BO_ 96 CAR_OVERALL_SIGNALS2: 64 XXX
 SG_ CRC1 : 7|8@0+ (1,0) [0|255] "" XXX
 SG_ COUNTER1 : 59|4@0+ (1,0) [0|15] "" XXX
 SG_ CRC2 : 71|8@0+ (1,0) [0|255] "" XXX
 SG_ GAS_POSITION : 79|8@0+ (0.393700787,0) [0|255] "%" XXX
 SG_ BRAKE_SIGNAL : 86|1@0+ (1,0) [0|1] "" XXX
 SG_ ACC_GAS_POSITION : 103|8@0+ (0.393700787,0) [0|255] "%" XXX
 SG_ COUNTER2 : 123|4@0+ (1,0) [0|15] "" XXX
 SG_ CRC3 : 135|8@0+ (1,0) [0|255] "" XXX
 SG_ REQ_REVIEW_UND_SIGNAL : 143|10@0+ (1,0) [0|255] "" XXX
 SG_ REQ_REVIEW_POWER_CONSUMPTION : 144|9@0+ (1,-175) [0|511] "" XXX
 SG_ REQ_REVIEW_POWER_CONSUMPTION2 : 180|9@0+ (1,-176) [0|511] "" XXX
 SG_ COUNTER3 : 187|4@0+ (1,0) [0|15] "" XXX
 SG_ REQ_REVIEW_POWER_STATE_SIGNAL : 302|4@0+ (1,0) [0|15] "" XXX
 SG_ REQ_REVIEW_POWER_STATE_SIGNAL2 : 370|1@0+ (1,0) [0|1] "" XXX

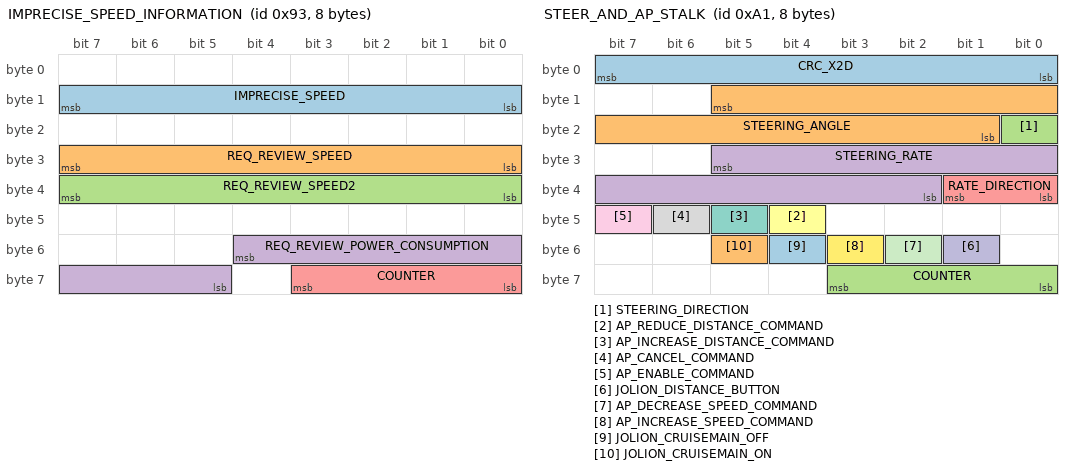
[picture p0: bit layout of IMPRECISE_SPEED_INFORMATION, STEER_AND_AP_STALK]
BO_ 147 IMPRECISE_SPEED_INFORMATION: 8 XXX
 SG_ IMPRECISE_SPEED : 15|8@0+ (3.5,0) [0|255] "kph" XXX
 SG_ REQ_REVIEW_SPEED : 31|8@0+ (0.430107526,0) [0|255] "Kph" XXX
 SG_ REQ_REVIEW_SPEED2 : 39|8@0+ (0.430107526,0) [0|255] "Kph" XXX
 SG_ REQ_REVIEW_POWER_CONSUMPTION : 52|8@0+ (1,0) [0|255] "" XXX
 SG_ COUNTER : 59|4@0+ (1,0) [0|15] "" XXX

BO_ 161 STEER_AND_AP_STALK: 8 XXX
 SG_ CRC_X2D : 7|8@0+ (1,0) [0|255] "" XXX
 SG_ STEERING_ANGLE : 13|13@0+ (0.1,0) [0|65535] "degs" XXX
 SG_ STEERING_DIRECTION : 16|1@0+ (1,0) [0|1] "" XXX
 SG_ STEERING_RATE : 29|12@0+ (0.004,0) [0|4095] "" XXX
 SG_ RATE_DIRECTION : 33|2@0+ (1,0) [0|3] "" XXX
 SG_ AP_REDUCE_DISTANCE_COMMAND : 44|1@0+ (1,0) [0|1] "" XXX
 SG_ AP_INCREASE_DISTANCE_COMMAND : 45|1@0+ (1,0) [0|1] "AUTOPILOT_STALK" XXX
 SG_ AP_CANCEL_COMMAND : 46|1@0+ (1,0) [0|1] "" XXX
 SG_ AP_ENABLE_COMMAND : 47|1@0+ (1,0) [0|1] "" XXX
 SG_ JOLION_DISTANCE_BUTTON : 49|1@0+ (1,0) [0|1] "" XXX
 SG_ AP_DECREASE_SPEED_COMMAND : 50|1@0+ (1,0) [0|1] "" XXX
 SG_ AP_INCREASE_SPEED_COMMAND : 51|1@0+ (1,0) [0|1] "" XXX
 SG_ JOLION_CRUISEMAIN_OFF : 52|1@0+ (1,0) [0|1] "" XXX
 SG_ JOLION_CRUISEMAIN_ON : 53|1@0+ (1,0) [0|1] "" XXX
 SG_ COUNTER : 59|4@0+ (1,0) [0|255] "" XXX

BO_ 259 SPEED: 64 XXX
 SG_ CRC : 199|8@0+ (1,0) [0|255] "" XXX
 SG_ UNDEFINED_ACCUMULATOR : 207|8@0+ (1,0) [0|255] "" XXX
 SG_ UNDEFINED_COUNTER : 215|8@0+ (1,0) [0|255] "" XXX
 SG_ ODD_GAS_POSITION : 231|8@0+ (1,0) [0|255] "" XXX
 SG_ SPEED : 239|8@0+ (1,0) [0|255] "Khp" XXX
 SG_ COUNTER2 : 251|4@0+ (1,0) [0|15] "" XXX

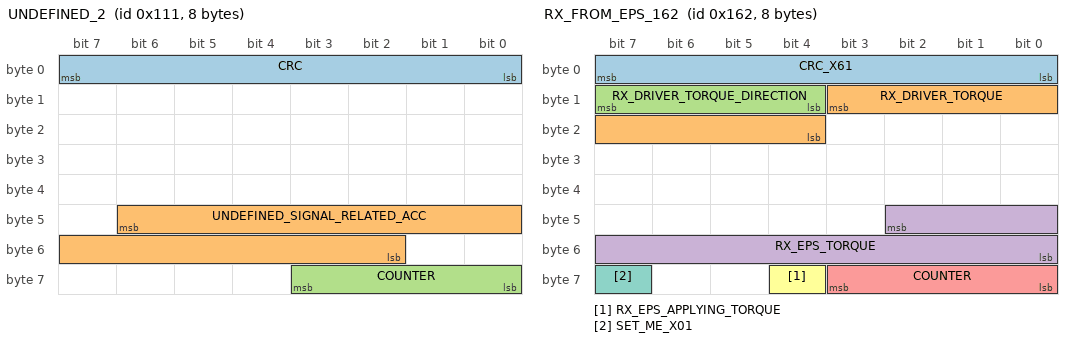
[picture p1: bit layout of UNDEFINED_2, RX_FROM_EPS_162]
BO_ 273 UNDEFINED_2: 8 XXX
 SG_ CRC : 7|8@0+ (1,0) [0|255] "" XXX
 SG_ UNDEFINED_SIGNAL_RELATED_ACC : 46|13@0+ (1,0) [0|8191] "" XXX
 SG_ COUNTER : 59|4@0+ (1,0) [0|15] "" XXX

BO_ 288 BRAKE2: 64 XXX
 SG_ CRC : 7|8@0+ (1,0) [0|255] "" XXX
 SG_ PEDAL_BRAKE_PRESSED : 11|1@0+ (1,0) [0|1] "" XXX
 SG_ REQ_REVIEW_MOVING : 22|1@0+ (1,0) [0|1] "" XXX
 SG_ USER_BRAKE : 37|4@0+ (1,0) [0|3] "" XXX
 SG_ REVIEW_REQ_BRAKE_SIGNAL2 : 47|8@0+ (1,0) [0|255] "" XXX
 SG_ COUNTER : 59|4@0+ (1,0) [0|15] "" XXX

BO_ 299 STEER_CMD: 64 XXX
 SG_ CRC_X9B : 71|8@0+ (1,0) [0|255] "" XXX
 SG_ TORQUE_REFLECTED : 73|8@0- (1,-1) [0|255] "" XXX
 SG_ BASIC_CHECKSUM : 78|5@0+ (1,0) [0|31] "" XXX
 SG_ SET_ME_X01 : 79|1@0+ (1,0) [0|1] "" XXX
 SG_ TORQUE_CMD : 102|10@0- (1,1) [0|511] "" XXX
 SG_ INVERT_DIRECTION : 103|1@0+ (1,0) [0|1] "" XXX
 SG_ COUNTER : 123|4@0+ (1,0) [0|15] "" XXX
 SG_ STEER_REQUEST : 125|1@0+ (1,0) [0|1] "" XXX
 SG_ CRC_X34 : 135|8@0+ (1,0) [0|255] "" XXX
 SG_ BYPASS_ME : 143|52@0+ (1,0) [0|1.84467440737096e+19] "" XXX
 SG_ COUNTER_X34 : 187|4@0+ (1,0) [0|15] "" XXX

BO_ 303 CAR_OVERALL_SIGNALS: 64 XXX
 SG_ CRC1 : 71|8@0+ (1,0) [0|255] "" XXX
 SG_ DRIVE_MODE_SIGNAL : 73|1@0+ (1,0) [0|1] "" XXX
 SG_ REQ_REVIEW_POWER_STATE : 80|1@0+ (1,0) [0|1] "" XXX
 SG_ REQ_REVIEW_POWER_STATE2 : 83|1@0+ (1,0) [0|1] "" XXX
 SG_ GAS_SIGNAL : 86|1@0+ (1,0) [0|1] "" XXX
 SG_ REQ_REVIEW_POWER_STATE3 : 113|1@0+ (1,0) [0|1] "" XXX
 SG_ COUNTER1 : 123|4@0+ (1,0) [0|15] "" XXX
 SG_ CRC2 : 135|8@0+ (1,0) [0|255] "" XXX
 SG_ DRIVER_MODE_SIGNAL2 : 161|1@0+ (1,0) [0|1] "" XXX
 SG_ DRIVE_MODE_P : 162|1@0+ (1,0) [0|1] "" XXX
 SG_ DRIVE_MODE_D : 163|1@0+ (1,0) [0|1] "" XXX
 SG_ DRIVE_MODE_SIGNAL3 : 165|1@0+ (1,0) [0|1] "" XXX
 SG_ DRIVE_MODE : 166|2@0+ (1,0) [0|1] "" XXX
 SG_ BRAKE_SIGNAL : 176|1@0+ (1,0) [0|1] "" XXX
 SG_ COUNTER2 : 187|4@0+ (1,0) [0|15] "" XXX

BO_ 311 BRAKE: 64 XXX
 SG_ CRC1 : 71|8@0+ (1,0) [0|255] "" XXX
 SG_ REQ_REVIEW_DRIVE_MODE : 77|1@0+ (1,0) [0|1] "" XXX
 SG_ COUNTER1 : 123|4@0+ (1,0) [0|15] "" XXX
 SG_ CRC2 : 135|8@0+ (1,0) [0|255] "" XXX
 SG_ REQ_REVIEW_HANDBRAKE_ENABLED : 143|1@0+ (1,0) [0|1] "" XXX
 SG_ BRAKE_SIGNAL1 : 152|1@0+ (1,0) [0|1] "" XXX
 SG_ REVIEW_REQ_HANDBRAKE_RELEASED : 153|1@0+ (1,0) [0|1] "" XXX
 SG_ REVIEW_REQ_HANDBRAKE_ENABLED : 154|1@0+ (1,0) [0|1] "DURING POWER BRAKE IS FALSE" XXX
 SG_ BRAKE_SIGNAL2 : 155|1@0+ (1,0) [0|1] "" XXX
 SG_ COUNTER2 : 187|4@0+ (1,0) [0|15] "" XXX
 SG_ CRC3 : 199|8@0+ (1,0) [0|255] "" XXX
 SG_ BRAKE_PRESSURE : 207|13@0+ (1,0) [0|8191] "" XXX
 SG_ COUNTER3 : 251|4@0+ (1,0) [0|15] "" XXX
 SG_ CRC4 : 263|8@0+ (1,0) [0|255] "" XXX

BO_ 315 WHEEL_SPEEDS: 64 XXX
 SG_ CRC_X7F : 7|8@0+ (1,0) [0|255] "" XXX
 SG_ FRONT_LEFT_WHEEL_SPEED : 12|13@0+ (0.05924739,0) [0|8191] "Kph" XXX
 SG_ FRONT_RIGHT_WHEEL_SPEED : 28|13@0+ (0.05924739,0) [0|8191] "Kph" XXX
 SG_ FRONT_DISTANCE_ACCUMULATOR : 47|16@0+ (1,0) [0|65535] "??" XXX
 SG_ COUNTER : 59|4@0+ (1,0) [0|15] "" XXX
 SG_ REAR_CRC : 327|8@0+ (1,0) [0|255] "" XXX
 SG_ REAR_LEFT_WHEEL_SPEED : 332|13@0+ (0.05924739,0) [0|8191] "Kph" XXX
 SG_ REAR_RIGHT_WHEEL_SPEED : 348|13@0+ (0.05924739,0) [0|8191] "Kph" XXX
 SG_ REAR_DISTANCE_ACCUMULATOR : 367|16@0+ (1,0) [0|65535] "" XXX
 SG_ REAR_COUNTER : 379|4@0+ (1,0) [0|15] "" XXX

BO_ 323 ACC_CMD: 64 XXX
 SG_ CRC_BRAKE_0xEF : 71|8@0+ (1,0) [0|255] "" XXX
 SG_ BRAKE_OR_GAS_REQ : 76|5@0+ (1,0) [0|15] "" XXX
 SG_ BYPASSME_1 : 87|18@0+ (1,0) [0|4294967295] "" XXX
 SG_ STANDSTILL_1 : 101|1@0+ (1,0) [0|1] "" XXX
 SG_ BRAKE_CMD : 111|8@0+ (1,-181) [0|255] "" XXX
 SG_ SPEED_REAL : 119|8@0+ (1,0) [0|255] "Kph" XXX
 SG_ COUNTER_BRAKE : 123|4@0+ (1,0) [0|15] "" XXX
 SG_ BYPASSME_2 : 135|64@0+ (1,0) [0|2.47588007857076e+27] "" XXX
 SG_ CRC_ACC_0x87 : 199|8@0+ (1,0) [0|255] "" XXX
 SG_ BYPASS_ACC1 : 207|16@0+ (1,0) [0|524287] "" XXX
 SG_ GAS_CMD : 220|13@0+ (1,-192) [0|4095] "" XXX
 SG_ STANDSTILL_2 : 223|3@0+ (1,0) [0|7] "" XXX
 SG_ BYPASS_ACC2 : 238|19@0+ (1,0) [0|1048575] "" XXX
 SG_ STANDSTILL_3 : 239|1@0+ (1,0) [0|1] "" XXX
 SG_ COUNTER_ACC : 251|4@0+ (1,0) [0|15] "" XXX

BO_ 327 RX_STEER_RELATED: 64 XXX
 SG_ A_CRC_X61 : 7|8@0+ (1,0) [0|255] "" XXX
 SG_ A_BYPASSME_2 : 8|45@0+ (1,0) [0|35184372088831] "" XXX
 SG_ A_RX_STEER_REQUESTED : 10|2@0+ (1,0) [0|3] "" XXX
 SG_ A_BYPASSME_1 : 15|5@0+ (1,0) [0|31] "" XXX
 SG_ A_COUNTER : 59|4@0+ (1,0) [0|15] "" XXX
 SG_ B_CRC_X61 : 71|8@0+ (1,0) [0|255] "" XXX
 SG_ B_RX_DRIVER_TORQUE : 78|11@0- (1,0) [0|4095] "" XXX
 SG_ B_BYPASSME_1 : 79|1@0+ (1,0) [0|1] "" XXX
 SG_ B_BYPASSME_2 : 83|25@0+ (1,0) [0|33554431] "" XXX
 SG_ B_RX_EPS_TORQUE : 106|11@0- (1,548) [0|262143] "" XXX
 SG_ B_COUNTER : 123|4@0+ (1,0) [0|15] "" XXX
 SG_ B_BYPASSME_4 : 124|1@0+ (1,0) [0|1] "" XXX
 SG_ EPS_FAULT_PERMANENT : 125|1@0+ (1,0) [0|1] "" XXX
 SG_ B_BYPASSME_3 : 127|2@0+ (1,0) [0|15] "" XXX

BO_ 347 FRONT_BUMPER: 64 XXX
 SG_ CENTRAL_DIST : 95|7@0- (1,0) [0|127] "" XXX

BO_ 354 RX_FROM_EPS_162: 8 XXX
 SG_ CRC_X61 : 7|8@0+ (1,0) [0|255] "" XXX
 SG_ RX_DRIVER_TORQUE : 11|8@0- (1,0) [0|4095] "" XXX
 SG_ RX_DRIVER_TORQUE_DIRECTION : 15|4@0+ (1,0) [0|15] "" XXX
 SG_ RX_EPS_TORQUE : 42|11@0- (1,548) [0|2047] "" XXX
 SG_ COUNTER : 59|4@0+ (1,0) [0|15] "" XXX
 SG_ RX_EPS_APPLYING_TORQUE : 60|1@0+ (1,0) [0|15] "" XXX
 SG_ SET_ME_X01 : 63|1@0+ (1,0) [0|1] "" XXX

BO_ 357 NEW_MSG_165: 8 XXX

BO_ 367 RADAR_BEHIND: 64 XXX
 SG_ BSM_RIGHT : 82|2@0+ (1,0) [0|3] "" XXX
 SG_ BSM_LEFT : 85|2@0+ (1,0) [0|3] "" XXX
 SG_ L_ADJACENT : 161|6@0+ (1,0) [0|63] "" XXX
 SG_ L_APPROACHING : 171|7@0+ (1,0) [0|127] "" XXX
 SG_ R_ADJACENT : 277|8@0- (1,0) [0|255] "" XXX
 SG_ R_APPROACHING : 291|8@0+ (1,0) [0|255] "" XXX

BO_ 412 LIGHTS: 16 XXX
 SG_ BRAKE_LIGHTS : 24|3@0+ (1,0) [0|7] "" XXX
 SG_ RIGHT_TURN_SIGNAL : 30|1@0+ (1,0) [0|1] "ON/OFF ACCORDINGLY LIGHT" XXX
 SG_ LEFT_TURN_SIGNAL : 31|1@0+ (1,0) [0|1] "ON/OFF ACCORDINGLY LIGHT" XXX

BO_ 415 NEW_MSG_19F: 64 XXX

BO_ 546 NEW_MSG_222: 64 XXX

BO_ 573 LATERAL_STATE: 64 XXX
 SG_ BYPASSME_1 : 71|32@0+ (1,0) [0|4294967295] "" XXX
 SG_ BYPASSME_2 : 103|32@0+ (1,0) [0|4294967295] "" XXX
 SG_ CRC_X66 : 135|8@0+ (1,0) [0|255] "" XXX
 SG_ LKAS_STATE : 141|3@0+ (1,0) [0|3] "" XXX
 SG_ BY_PASSME : 146|39@0+ (1,0) [0|549755813887] "" XXX
 SG_ CRUISE_STATE : 151|5@0+ (1,0) [0|7] "" XXX
 SG_ COUNTER : 187|4@0+ (1,0) [0|15] "" XXX
 SG_ BYPASSME_3 : 199|32@0+ (1,0) [0|4294967295] "" XXX
 SG_ BYPASSME_4 : 231|32@0+ (1,0) [0|4294967295] "" XXX
 SG_ BYPASSME_5 : 263|32@0+ (1,0) [0|4294967295] "" XXX
 SG_ BYPASSME_6 : 295|32@0+ (1,0) [0|4294967295] "" XXX

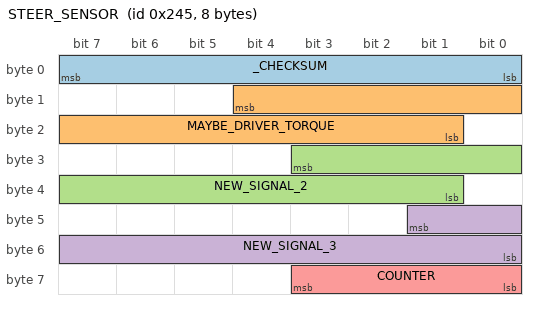
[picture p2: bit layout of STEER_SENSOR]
BO_ 581 STEER_SENSOR: 8 XXX
 SG_ _CHECKSUM : 7|8@0+ (1,0) [0|255] "" XXX
 SG_ MAYBE_DRIVER_TORQUE : 12|12@0+ (1,0) [0|2047] "" XXX
 SG_ NEW_SIGNAL_2 : 27|11@0+ (1,0) [0|2047] "" XXX
 SG_ NEW_SIGNAL_3 : 41|10@0+ (1,0) [0|1023] "" XXX
 SG_ COUNTER : 59|4@0+ (1,0) [0|15] "" XXX

BO_ 639 NEW_MSG_27F: 16 XXX
 SG_ CRC : 7|8@0+ (1,0) [0|255] "" XXX
 SG_ REQ_REVIEW_ODOMETER : 23|16@0+ (1,0) [0|65535] "" XXX
 SG_ COUNTER : 59|4@0+ (1,0) [0|15] "" XXX

BO_ 649 DRIVE_MODE: 64 XXX
 SG_ DRIVE_MODE_ENABLED : 382|1@0+ (1,0) [0|1] "" XXX
 SG_ DRIVE_MODE_DISABLED : 383|1@0+ (1,0) [0|1] "" XXX

BO_ 671 NEW_MSG_29F: 8 XXX
 SG_ NEW_SIGNAL_1 : 41|6@0+ (1,0) [0|63] "" XXX

BO_ 683 ACC: 64 XXX
 SG_ COUNTER1 : 123|4@0+ (1,0) [0|15] "" XXX
 SG_ CRC1 : 135|8@0+ (1,0) [0|255] "" XXX
 SG_ CRUISE_STATE_2 : 149|3@0+ (1,0) [0|7] "" XXX
 SG_ CAR_DISTANCE_SELECTION : 170|3@0+ (1,0) [0|7] "" XXX
 SG_ ACC_SPEED_SELECTION : 183|8@0+ (1,0) [0|255] "Kph" XXX
 SG_ COUNTER2 : 187|4@0+ (1,0) [0|15] "" XXX

BO_ 696 UNDEFINED_INTERESTING_SIGNALS: 64 XXX
 SG_ UNDEFINED_SIGNAL2 : 20|9@0+ (1,0) [0|511] "" XXX
 SG_ UNDEFINED_SIGNAL1 : 27|12@0+ (1,0) [0|4095] "" XXX
 SG_ LEAD_DISTANCE : 26|11@0+ (0.0625,0) [0|127.94] "m" XXX
 SG_ LEAD_SPEED : 23|13@0+ (0.03125,-128) [-128|127.97] "m/s" XXX
 SG_ LEAD_STATE : 70|2@0+ (1,0) [0|3] "" XXX
 SG_ LEAD_LATERAL : 79|10@0+ (-0.0625,32) [-32|32] "m" XXX
 SG_ UNDEFINED_ACCUMULATOR : 47|8@0+ (1,0) [0|255] "" XXX
 SG_ UNDEFINED_ACCUMULATOR2 : 47|12@0+ (1,0) [0|15] "" XXX
 SG_ UNDEFINED_SIGNAL3 : 51|12@0+ (1,0) [0|4095] "" XXX
 SG_ UNDEFINED_SIGNAL4 : 265|10@0+ (1,0) [0|1023] "" XXX
 SG_ NEW_SIGNAL_1 : 354|7@0+ (1,0) [0|127] "" XXX

BO_ 714 BUTTONS: 8 XXX
 SG_ LOCK_DOORS_BUTTON : 16|1@0+ (1,0) [0|1] "" XXX

BO_ 793 DOOR_DRIVER: 16 XXX
 SG_ REQ_REVIEW_CAR_STATE : 16|1@0+ (1,0) [0|1] "" XXX
 SG_ DOOR_REAR_RIGHT_OPEN : 19|1@0+ (1,0) [0|1] "" XXX
 SG_ DOOR_FRONT_RIGHT_OPEN : 20|1@0+ (1,0) [0|1] "" XXX
 SG_ DOOR_REAR_LEFT_OPEN : 21|1@0+ (1,0) [0|1] "" XXX
 SG_ DOOR_DRIVER_OPEN : 22|1@0+ (1,0) [0|1] "" XXX

BO_ 837 DOOR_LOCK_STATES: 16 XXX
 SG_ DOOR_LOCK_STATE : 13|1@0+ (1,0) [0|1] "" XXX
 SG_ DOOR_LOCK_STATE2 : 34|1@0+ (1,0) [0|1] "" XXX

BO_ 849 SEATBELT: 16 XXX
 SG_ CRC : 7|8@0+ (1,0) [0|255] "" XXX
 SG_ SEAT_BELT_DRIVER_STATE : 11|1@0+ (1,0) [0|1] "" XXX
 SG_ SEAT_BELT_DRIVER_STATE2 : 24|1@0+ (1,0) [0|1] "" XXX
 SG_ COUNTER : 59|4@0+ (1,0) [0|15] "" XXX

CM_ SG_ 96 GAS_POSITION "0 - 100%";
CM_ SG_ 96 BRAKE_SIGNAL "1 = BRAKE PRESSED";
CM_ SG_ 96 ACC_GAS_POSITION "0 - 100% | WHEN ACC REMAINS INFORMATION";
CM_ SG_ 96 REQ_REVIEW_POWER_CONSUMPTION2 "REQ FACTOR CONVERTER";
CM_ SG_ 96 REQ_REVIEW_POWER_STATE_SIGNAL "1 = OFF | 12 WARM-UP | 5 = ON";
CM_ SG_ 96 REQ_REVIEW_POWER_STATE_SIGNAL2 "1 = OFF | 0 = ON";
CM_ SG_ 147 IMPRECISE_SPEED "lower precision, reverse is positive as well";
CM_ SG_ 147 REQ_REVIEW_SPEED "INITIALLY ADJUSTED TO KPH BUT ITS NOT";
CM_ SG_ 147 REQ_REVIEW_SPEED2 "INITIALLY ADJUSTED TO KPH BUT ITS NOT";
CM_ SG_ 161 STEERING_ANGLE "0 CENTER, NO LEFT / RIGHT SIGNAL";
CM_ SG_ 696 LEAD_DISTANCE "fused radar/camera distance to the ACC target; 0 when LEAD_STATE = 0";
CM_ SG_ 696 LEAD_SPEED "absolute ground speed of the ACC target; forced to 0 when LEAD_STATE = 3";
CM_ SG_ 696 LEAD_STATE "ACC target status; use only 1 and 3 as a valid lead";
CM_ SG_ 696 LEAD_LATERAL "TENTATIVE: lateral offset of the ACC target, left positive; raw 512 = centered, scale not confirmed (0.04-0.07 m/bit fitted)";
CM_ SG_ 161 STEERING_DIRECTION "0 is counterclockwise and 1 is clockwise";
CM_ SG_ 161 STEERING_RATE "Peak identified 3680, 0 = stopped";
CM_ SG_ 161 AP_REDUCE_DISTANCE_COMMAND "AUTOPILOT STALK";
CM_ SG_ 161 AP_CANCEL_COMMAND "AUTOPILOT STALK - FRONT MOVEMENT = CANCEL COMMAND";
CM_ SG_ 161 AP_ENABLE_COMMAND "AUTOPILOT STALK - REAR MOVEMENT = ENABLE COMMAND";
CM_ SG_ 161 AP_DECREASE_SPEED_COMMAND "AUTOPILOT STALK - MOVEMENT";
CM_ SG_ 161 AP_INCREASE_SPEED_COMMAND "AUTOPILOT STALK - DOWN MOVEMENT";
CM_ SG_ 259 UNDEFINED_ACCUMULATOR "WHEN ELECTRIC MODE = 0, PERHAPS COMBUSTION ENGINE";
CM_ SG_ 259 UNDEFINED_COUNTER "0 WHEN ELECTRIC, PERHAPS COMBUSTION ENGINE";
CM_ SG_ 259 ODD_GAS_POSITION "17 = 0, 253 = FULL, SOMETIMES 4";
CM_ SG_ 259 SPEED "PRECISE, KPH, DASHBOARD SPEED, BIT LOWER THAN GPS SPEED";
CM_ SG_ 288 REQ_REVIEW_MOVING "1 = CAR IS MOVING";
CM_ SG_ 288 REVIEW_REQ_BRAKE_SIGNAL2 "0 | 128 BRAKE PRESSED";
CM_ SG_ 299 STEER_REQUEST "1 = ON | 0 = OFF";
CM_ SG_ 303 DRIVE_MODE_SIGNAL "D/R = 0 | N/P = 1";
CM_ SG_ 303 REQ_REVIEW_POWER_STATE "1 = ON | 0 = IDLE";
CM_ SG_ 303 REQ_REVIEW_POWER_STATE2 "1 = ON | 0 = IDLE";
CM_ SG_ 303 GAS_SIGNAL "1 = GAS PRESSED";
CM_ SG_ 303 REQ_REVIEW_POWER_STATE3 "0 = OFF / 1 = ON";
CM_ SG_ 303 DRIVER_MODE_SIGNAL2 "D/R = 1 | N/P=0";
CM_ SG_ 303 DRIVE_MODE_SIGNAL3 "P/R = 1 | P/N = 0";
CM_ SG_ 303 DRIVE_MODE "0 = P | 1 = D | 2 = N | 3 = R (GOOD SIGNAL)";
CM_ SG_ 303 BRAKE_SIGNAL "1 BRAKE PRESSED";
CM_ SG_ 311 REQ_REVIEW_DRIVE_MODE "1 = P | 0 = D";
CM_ SG_ 311 BRAKE_SIGNAL1 "0 = NO | 1 = BRAKE PRESSED";
CM_ SG_ 311 REVIEW_REQ_HANDBRAKE_RELEASED "DURING POWER BRAKE IS TRUE";
CM_ SG_ 311 BRAKE_SIGNAL2 "0 NO | 1 = BRAKE PRESSED";
CM_ SG_ 311 BRAKE_PRESSURE "MAX PRESSURE IDENTIFIED = 4184 | 0 = NO PRESSURE";
CM_ SG_ 315 FRONT_LEFT_WHEEL_SPEED "Based on the car's dashboard speed";
CM_ SG_ 315 FRONT_RIGHT_WHEEL_SPEED "Based on the car's dashboard speed";
CM_ SG_ 315 FRONT_DISTANCE_ACCUMULATOR "?? doubts";
CM_ SG_ 315 REAR_LEFT_WHEEL_SPEED "Based on the car's dashboard speed";
CM_ SG_ 315 REAR_RIGHT_WHEEL_SPEED "Based on the car's dashboard speed";
CM_ SG_ 315 REAR_DISTANCE_ACCUMULATOR "PULSES";
CM_ SG_ 323 SPEED_REAL "PRECISE, EQUAL GPS SPEED";
CM_ SG_ 412 BRAKE_LIGHTS "POSSIBLE 3 DIFFERENT LIGHTS";
CM_ SG_ 412 LEFT_TURN_SIGNAL "ON/OFF ACCORDINGLY LIGHT";
CM_ BO_ 573 "HAVE LATERAL STATE INFO";
CM_ BO_ 649 "FRONT";
CM_ SG_ 649 DRIVE_MODE_ENABLED "DRIVE = 1 | OTHER MODES = 0";
CM_ SG_ 649 DRIVE_MODE_DISABLED "D = 0 | OTHER MODES = 0";
CM_ SG_ 683 CAR_DISTANCE_SELECTION "AUTOPILOT CAR DISTANCE SELECTED BY DRIVER, OPTIONS 1, 2, 3, 4";
CM_ BO_ 696 "POSSIBLE RELATED TO ACC OR ENGINE";
CM_ SG_ 714 LOCK_DOORS_BUTTON "1 = PRESSED";
CM_ SG_ 793 REQ_REVIEW_CAR_STATE "1 = STOPPED | 0 = MOVING";
CM_ SG_ 837 DOOR_LOCK_STATE "0 = LOCKED / 1 = UNLOCKED";
CM_ SG_ 837 DOOR_LOCK_STATE2 "0 = LOCKED / 1 = UNLOCKED";
CM_ SG_ 849 SEAT_BELT_DRIVER_STATE "0 = Fastened / 1 = Released";
CM_ SG_ 849 SEAT_BELT_DRIVER_STATE2 "0 = Fastened / 1 = Released";
VAL_ 161 RATE_DIRECTION 1 "clockwise" 2 "clockwise" 3 "clockwise";
VAL_ 323 BRAKE_OR_GAS_REQ 12 "GAS_REQ" 13 "BRAKE_REQ";
VAL_ 323 STANDSTILL_2 3 "active" 4 "inactive";
VAL_ 323 STANDSTILL_3 0 "active" 1 "inactive";
VAL_ 354 RX_DRIVER_TORQUE_DIRECTION 7 "clockwise right" 8 "counterclockwise left";
VAL_ 573 LKAS_STATE 5 "active" 2 "require_hands_on_steer" 3 "drift_out_left" 4 "drift_out_right";
VAL_ 683 CRUISE_STATE_2 0 "deactivated" 1 "deactivated" 2 "deactivated" 3 "activated" 4 "activated" 5 "activated" 6 "activated" 7 "activated";
VAL_ 696 LEAD_STATE 0 "none" 1 "moving" 2 "candidate" 3 "stopped";
